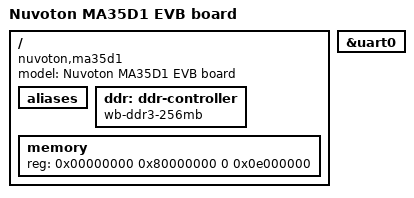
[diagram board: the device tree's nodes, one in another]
// SPDX-License-Identifier:
/*
 * Copyright 2020 - Nuvoton Technology Corporation
 *
 */

/dts-v1/;
#include "ma35d1.dtsi"

/ {
	model = "Nuvoton MA35D1 EVB board";
	compatible = "nuvoton,ma35d1";

	aliases {

	};

	ddr: ddr-controller {
		compatible = "wb-ddr3-256mb";
	};

	memory {
		device_type = "memory";
		reg = <0x00000000 0x80000000 0 0x0e000000>;
	};

};

&uart0 {
	status = "okay";
};





